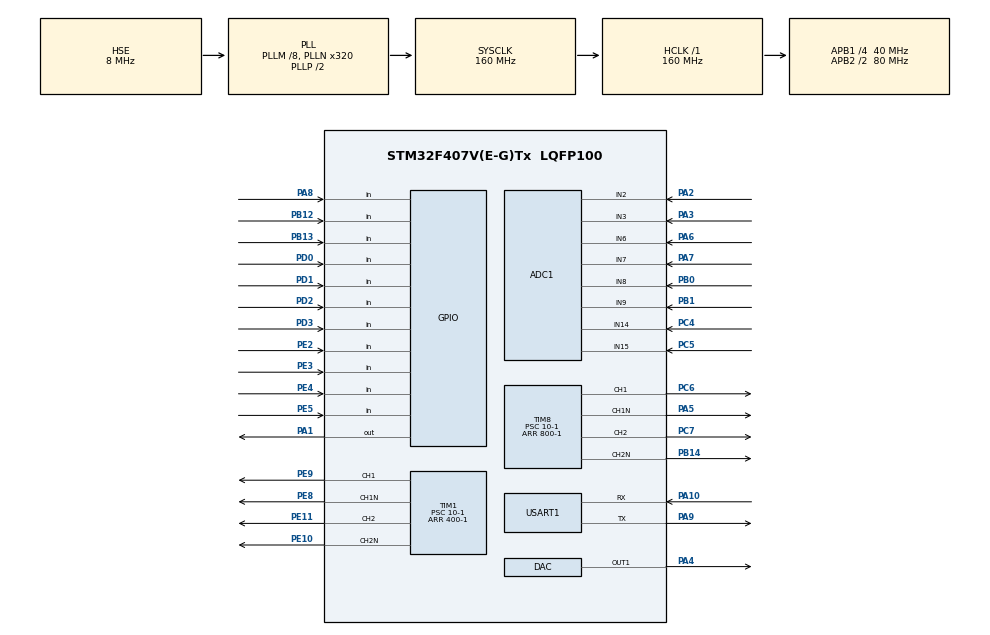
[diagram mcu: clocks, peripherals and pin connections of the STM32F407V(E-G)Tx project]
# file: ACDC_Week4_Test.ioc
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ADC1.Channel-0\#ChannelRegularConversion=ADC_CHANNEL_2
ADC1.Channel-1\#ChannelRegularConversion=ADC_CHANNEL_3
ADC1.Channel-2\#ChannelRegularConversion=ADC_CHANNEL_6
ADC1.Channel-3\#ChannelRegularConversion=ADC_CHANNEL_7
ADC1.Channel-4\#ChannelRegularConversion=ADC_CHANNEL_8
ADC1.Channel-5\#ChannelRegularConversion=ADC_CHANNEL_9
ADC1.Channel-6\#ChannelRegularConversion=ADC_CHANNEL_14
ADC1.Channel-7\#ChannelRegularConversion=ADC_CHANNEL_15
ADC1.ContinuousConvMode=ENABLE
ADC1.DMAContinuousRequests=ENABLE
ADC1.NbrOfConversion=8
ADC1.NbrOfConversionFlag=1
ADC1.Rank-0\#ChannelRegularConversion=1
ADC1.Rank-1\#ChannelRegularConversion=2
ADC1.Rank-2\#ChannelRegularConversion=3
ADC1.Rank-3\#ChannelRegularConversion=4
ADC1.Rank-4\#ChannelRegularConversion=5
ADC1.Rank-5\#ChannelRegularConversion=6
ADC1.Rank-6\#ChannelRegularConversion=7
ADC1.Rank-7\#ChannelRegularConversion=8
ADC1.SamplingTime-0\#ChannelRegularConversion=ADC_SAMPLETIME_3CYCLES
ADC1.SamplingTime-1\#ChannelRegularConversion=ADC_SAMPLETIME_3CYCLES
ADC1.SamplingTime-2\#ChannelRegularConversion=ADC_SAMPLETIME_3CYCLES
ADC1.SamplingTime-3\#ChannelRegularConversion=ADC_SAMPLETIME_3CYCLES
ADC1.SamplingTime-4\#ChannelRegularConversion=ADC_SAMPLETIME_3CYCLES
ADC1.SamplingTime-5\#ChannelRegularConversion=ADC_SAMPLETIME_3CYCLES
ADC1.SamplingTime-6\#ChannelRegularConversion=ADC_SAMPLETIME_3CYCLES
ADC1.SamplingTime-7\#ChannelRegularConversion=ADC_SAMPLETIME_3CYCLES
ADC1.ScanConvMode=ENABLE
ADC1.master=1
Dma.ADC1.0.Direction=DMA_PERIPH_TO_MEMORY
Dma.ADC1.0.FIFOMode=DMA_FIFOMODE_DISABLE
Dma.ADC1.0.Instance=DMA2_Stream0
Dma.ADC1.0.MemDataAlignment=DMA_MDATAALIGN_WORD
Dma.ADC1.0.MemInc=DMA_MINC_ENABLE
Dma.ADC1.0.Mode=DMA_CIRCULAR
Dma.ADC1.0.PeriphDataAlignment=DMA_PDATAALIGN_WORD
Dma.ADC1.0.PeriphInc=DMA_PINC_DISABLE
Dma.ADC1.0.Priority=DMA_PRIORITY_LOW
Dma.Request0=ADC1
Mcu.Family=STM32F4
Mcu.Name=STM32F407V(E-G)Tx
Mcu.Package=LQFP100
NVIC.DMA2_Stream0_IRQn=true\:1\:0\:true\:false\:true\:false\:true\:true
NVIC.PriorityGroup=NVIC_PRIORITYGROUP_3
NVIC.TIM1_UP_TIM10_IRQn=true\:0\:0\:false\:false\:true\:true\:true\:true
NVIC.TIM2_IRQn=true\:0\:0\:false\:false\:true\:true\:true\:true
NVIC.USART1_IRQn=true\:1\:1\:true\:false\:true\:true\:true\:true
PA1.Signal=GPIO_Output
PA10.Mode=Asynchronous
PA10.Signal=USART1_RX
PA2.Signal=ADCx_IN2
PA3.Signal=ADCx_IN3
PA4.Signal=COMP_DAC1_group
PA5.Mode=PWM Generation1 CH1 CH1N
PA5.Signal=TIM8_CH1N
PA6.Signal=ADCx_IN6
PA7.Signal=ADCx_IN7
PA8.GPIO_PuPd=GPIO_PULLUP
PA8.Signal=GPIO_Input
PA9.Mode=Asynchronous
PA9.Signal=USART1_TX
PB0.Signal=ADCx_IN8
PB1.Signal=ADCx_IN9
PB12.GPIO_PuPd=GPIO_PULLUP
PB12.Signal=GPIO_Input
PB13.GPIO_PuPd=GPIO_PULLUP
PB13.Signal=GPIO_Input
PB14.Mode=PWM Generation2 CH2 CH2N
PB14.Signal=TIM8_CH2N
PC4.Signal=ADCx_IN14
PC5.Signal=ADCx_IN15
PC6.Signal=S_TIM8_CH1
PC7.Signal=S_TIM8_CH2
PD0.GPIO_PuPd=GPIO_PULLUP
PD0.Signal=GPIO_Input
PD1.GPIO_PuPd=GPIO_PULLUP
PD1.Signal=GPIO_Input
PD2.GPIO_PuPd=GPIO_PULLUP
PD2.Signal=GPIO_Input
PD3.GPIO_PuPd=GPIO_PULLUP
PD3.Signal=GPIO_Input
PE10.Mode=PWM Generation2 CH2 CH2N
PE10.Signal=TIM1_CH2N
PE11.Signal=S_TIM1_CH2
PE2.GPIO_PuPd=GPIO_PULLUP
PE2.Signal=GPIO_Input
PE3.GPIO_PuPd=GPIO_PULLUP
PE3.Signal=GPIO_Input
PE4.GPIO_PuPd=GPIO_PULLUP
PE4.Signal=GPIO_Input
PE5.GPIO_PuPd=GPIO_PULLUP
PE5.Signal=GPIO_Input
PE8.Mode=PWM Generation1 CH1 CH1N
PE8.Signal=TIM1_CH1N
PE9.Signal=S_TIM1_CH1
PH0-OSC_IN.Mode=HSE-External-Oscillator
PH0-OSC_IN.Signal=RCC_OSC_IN
PH1-OSC_OUT.Mode=HSE-External-Oscillator
PH1-OSC_OUT.Signal=RCC_OSC_OUT
ProjectManager.HeapSize=0x200
ProjectManager.StackSize=0x400
ProjectManager.TargetToolchain=STM32CubeIDE
RCC.48MHZClocksFreq_Value=80000000
RCC.AHBFreq_Value=160000000
RCC.APB1CLKDivider=RCC_HCLK_DIV4
RCC.APB1Freq_Value=40000000
RCC.APB1TimFreq_Value=80000000
RCC.APB2CLKDivider=RCC_HCLK_DIV2
RCC.APB2Freq_Value=80000000
RCC.APB2TimFreq_Value=160000000
RCC.CortexFreq_Value=160000000
RCC.HCLKFreq_Value=160000000
RCC.HSE_VALUE=8000000
RCC.HSI_VALUE=16000000
RCC.LSE_VALUE=32768
RCC.PLLM=8
RCC.PLLN=320
RCC.PLLSourceVirtual=RCC_PLLSOURCE_HSE
RCC.SYSCLKFreq_VALUE=160000000
RCC.SYSCLKSource=RCC_SYSCLKSOURCE_PLLCLK
RCC.VCOOutputFreq_Value=320000000
SH.ADCx_IN14.0=ADC1_IN14,IN14
SH.ADCx_IN15.0=ADC1_IN15,IN15
SH.ADCx_IN2.0=ADC1_IN2,IN2
SH.ADCx_IN3.0=ADC1_IN3,IN3
SH.ADCx_IN6.0=ADC1_IN6,IN6
SH.ADCx_IN7.0=ADC1_IN7,IN7
SH.ADCx_IN8.0=ADC1_IN8,IN8
SH.ADCx_IN9.0=ADC1_IN9,IN9
SH.COMP_DAC1_group.0=DAC_OUT1,DAC_OUT1
SH.S_TIM1_CH1.0=TIM1_CH1,PWM Generation1 CH1 CH1N
SH.S_TIM1_CH2.0=TIM1_CH2,PWM Generation2 CH2 CH2N
SH.S_TIM8_CH1.0=TIM8_CH1,PWM Generation1 CH1 CH1N
SH.S_TIM8_CH2.0=TIM8_CH2,PWM Generation2 CH2 CH2N
STMicroelectronics.X-CUBE-ALGOBUILD.1.3.0.LibraryCcDSPOoLibraryJjDSPOoLibrary=true
TIM1.Channel-PWM\ Generation1\ CH1\ CH1N=TIM_CHANNEL_1
TIM1.Channel-PWM\ Generation2\ CH2\ CH2N=TIM_CHANNEL_2
TIM1.CounterMode=TIM_COUNTERMODE_CENTERALIGNED1
TIM1.DeadTime=10
TIM1.Period=400-1
TIM1.Prescaler=10-1
TIM2.CounterMode=TIM_COUNTERMODE_CENTERALIGNED1
TIM2.Period=400-1
TIM2.Prescaler=10-1
TIM8.Channel-PWM\ Generation1\ CH1\ CH1N=TIM_CHANNEL_1
TIM8.Channel-PWM\ Generation2\ CH2\ CH2N=TIM_CHANNEL_2
TIM8.CounterMode=TIM_COUNTERMODE_CENTERALIGNED1
TIM8.DeadTime=10
TIM8.Period=800-1
TIM8.Prescaler=10-1
USART1.VirtualMode=VM_ASYNC
VP_STMicroelectronics.X-CUBE-ALGOBUILD_VS_DSPOoLibraryJjLibrary_1.3.0_1.3.0.Mode=DSPOoLibraryJjLibrary
VP_TIM1_VS_ClockSourceINT.Mode=Internal
VP_TIM2_VS_ClockSourceINT.Mode=Internal
VP_TIM8_VS_ClockSourceINT.Mode=Internal
board=custom

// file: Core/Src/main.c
/* USER CODE BEGIN Header */
/**
  ******************************************************************************
  * @file           : main.c
  * @brief          : Main program body
  ******************************************************************************
  * @attention
  *
  * Copyright (c) 2022 STMicroelectronics.
  * All rights reserved.
  *
  * This software is licensed under terms that can be found in the LICENSE file
  * in the root directory of this software component.
  * If no LICENSE file comes with this software, it is provided AS-IS.
  *
  ******************************************************************************
  */
/* USER CODE END Header */
#include "main.h"
#include "adc.h"
#include "dac.h"
#include "dma.h"
#include "tim.h"
#include "usart.h"
#include "gpio.h"

/* USER CODE BEGIN Includes */
#include "arm_math.h"
/* USER CODE END Includes */

void SystemClock_Config(void);

/* USER CODE BEGIN 0 */
extern uint32_t ADC_Value[];
extern pid_p PLL,pid_Udc,pid_I1d,pid_I1q;
extern int flag_Start_Running;
extern float thetas;
/* USER CODE END 0 */

int main(void)
{

  /* MCU Configuration--------------------------------------------------------*/

  /* Reset of all peripherals, Initializes the Flash interface and the Systick. */
  HAL_Init();

  /* Configure the system clock */
  SystemClock_Config();

  /* Initialize all configured peripherals */
  MX_GPIO_Init();
  MX_DMA_Init();
  MX_ADC1_Init();
  MX_TIM1_Init();
  MX_TIM2_Init();
  MX_DAC_Init();
  MX_USART1_UART_Init();
  MX_TIM8_Init();
  /* USER CODE BEGIN 2 */

  HAL_Delay(1000);
	printf("BL(0);\r\n");
	HAL_Delay(40);

//  Keyboard_Init();

  //TIM中断控制程序打开
  HAL_TIM_Base_Start_IT(&htim2);
  //ADC
  HAL_ADC_Start_DMA(&hadc1, (uint32_t*)&ADC_Value, ADC_num);

  HAL_DAC_Start(&hdac, DAC_CHANNEL_1);

  //注意KPKI 在幅值为1时根据Simulink得到对应的是314 1725，可以根据此来定
  //20Vp Vs 20 100, Reset 才能正常使用10V时，就做了延�????????
  PID_init(&PLL,20,180,0,500,100,314,Control_Time);

  //通过验证锁相成功后再打开 在TIM1中断
//  PID_init(&pid_Udc,0.3555f,39.934f,0,10,-10,0,1/Control_Frequency);
//  PID_init(&pid_Isd,0.4632f,40.0f,0,10,-10,0,1/Control_Frequency);
//  HAL_TIM_PWM_Start(&htim1, TIM_CHANNEL_1);
//  HAL_TIM_PWM_Start(&htim1, TIM_CHANNEL_2);
//  HAL_TIMEx_PWMN_Start(&htim1,TIM_CHANNEL_1);
//  HAL_TIMEx_PWMN_Start(&htim1,TIM_CHANNEL_2);

//	HAL_TIM_PWM_Start(&htim8, TIM_CHANNEL_1);
//	HAL_TIM_PWM_Start(&htim8, TIM_CHANNEL_2);
//	HAL_TIMEx_PWMN_Start(&htim8,TIM_CHANNEL_1);
//	HAL_TIMEx_PWMN_Start(&htim8,TIM_CHANNEL_2);
  /* USER CODE END 2 */

  /* Infinite loop */
  while (1)
  {

    /* USER CODE BEGIN 3 */
	  Screen_Print();
  }
  /* USER CODE END 3 */
}

void SystemClock_Config(void)
{
  RCC_OscInitTypeDef RCC_OscInitStruct = {0};
  RCC_ClkInitTypeDef RCC_ClkInitStruct = {0};

  /** Configure the main internal regulator output voltage
  */
  __HAL_RCC_PWR_CLK_ENABLE();
  __HAL_PWR_VOLTAGESCALING_CONFIG(PWR_REGULATOR_VOLTAGE_SCALE1);
  /** Initializes the RCC Oscillators according to the specified parameters
  * in the RCC_OscInitTypeDef structure.
  */
  RCC_OscInitStruct.OscillatorType = RCC_OSCILLATORTYPE_HSE;
  RCC_OscInitStruct.HSEState = RCC_HSE_ON;
  RCC_OscInitStruct.PLL.PLLState = RCC_PLL_ON;
  RCC_OscInitStruct.PLL.PLLSource = RCC_PLLSOURCE_HSE;
  RCC_OscInitStruct.PLL.PLLM = 8;
  RCC_OscInitStruct.PLL.PLLN = 320;
  RCC_OscInitStruct.PLL.PLLP = RCC_PLLP_DIV2;
  RCC_OscInitStruct.PLL.PLLQ = 4;
  if (HAL_RCC_OscConfig(&RCC_OscInitStruct) != HAL_OK)
  {
    Error_Handler();
  }
  /** Initializes the CPU, AHB and APB buses clocks
  */
  RCC_ClkInitStruct.ClockType = RCC_CLOCKTYPE_HCLK|RCC_CLOCKTYPE_SYSCLK
                              |RCC_CLOCKTYPE_PCLK1|RCC_CLOCKTYPE_PCLK2;
  RCC_ClkInitStruct.SYSCLKSource = RCC_SYSCLKSOURCE_PLLCLK;
  RCC_ClkInitStruct.AHBCLKDivider = RCC_SYSCLK_DIV1;
  RCC_ClkInitStruct.APB1CLKDivider = RCC_HCLK_DIV4;
  RCC_ClkInitStruct.APB2CLKDivider = RCC_HCLK_DIV2;

  if (HAL_RCC_ClockConfig(&RCC_ClkInitStruct, FLASH_LATENCY_5) != HAL_OK)
  {
    Error_Handler();
  }
}

void Error_Handler(void)
{
  __disable_irq();
  while (1)
  {
  }
}
